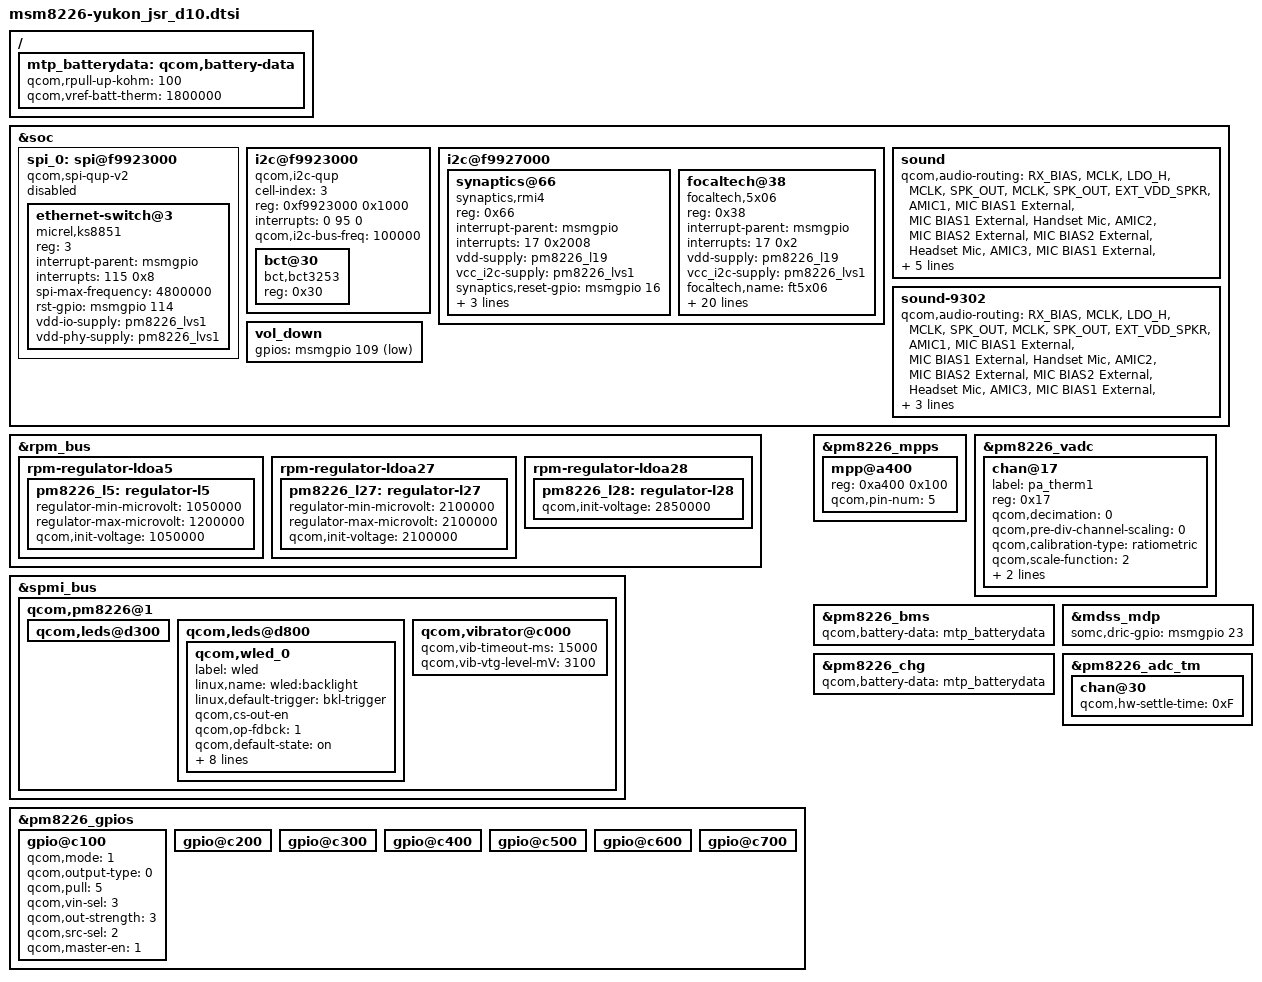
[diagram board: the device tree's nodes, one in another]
/* Copyright (c) 2013-2016, The Linux Foundation. All rights reserved.
 *
 * This program is free software; you can redistribute it and/or modify
 * it under the terms of the GNU General Public License version 2 and
 * only version 2 as published by the Free Software Foundation.
 *
 * This program is distributed in the hope that it will be useful,
 * but WITHOUT ANY WARRANTY; without even the implied warranty of
 * MERCHANTABILITY or FITNESS FOR A PARTICULAR PURPOSE.  See the
 * GNU General Public License for more details.
 */

#include "msm8226-yukon_common.dtsi"
#include "dsi-panel-nt35590-720p-auo-video.dtsi"
#include "dsi-panel-nt35590-720p-cmi-video.dtsi"
#include "dsi-panel-nt35521-720p-auo-asi-video.dtsi"
#include "dsi-panel-nt35521-720p-lg-video.dtsi"

&soc {
	spi@f9923000 {
		ethernet-switch@3 {
			compatible = "micrel,ks8851";
			reg = <3>;
			interrupt-parent = <&msmgpio>;
			interrupts = <115 0x8>;
			spi-max-frequency = <4800000>;
			rst-gpio = <&msmgpio 114 0>;
			vdd-io-supply = <&pm8226_lvs1>;
			vdd-phy-supply = <&pm8226_lvs1>;
		};
	};

	i2c@f9923000 {    /* BLSP-1 QUP-1 */
		cell-index = <3>;
		compatible = "qcom,i2c-qup";
		reg = <0xf9923000 0x1000>;
		#address-cells = <0x1>;
		#size-cells = <0x0>;
		reg-names = "qup_phys_addr";
		interrupts = <0 95 0>;
		interrupt-names = "qup_err_intr";
		qcom,i2c-bus-freq = <100000>;
		/* ---- msm-tricolor-leds ----  */
		bct@30 {
			compatible = "bct,bct3253";
			reg = <0x30>;
		};
	};

	i2c@f9927000 { /* BLSP1 QUP5 */
		synaptics@66 {
			compatible = "synaptics,rmi4";
			reg = <0x66>;
			interrupt-parent = <&msmgpio>;
			interrupts = <17 0x2008>;
			vdd-supply = <&pm8226_l19>;
			vcc_i2c-supply = <&pm8226_lvs1>;
			synaptics,reset-gpio = <&msmgpio 16 0x00>;
			synaptics,irq-gpio = <&msmgpio 17 0x2008>;
			synaptics,button-map = <139 102 158>;
			synaptics,i2c-pull-up;
			/* synaptics,power-down;    */ /* fully power down regulators in suspend  */
			/* synaptics,disable-gpios; */ /* specify to disable gpios in suspend (power saving) */
		};

		focaltech@38 {
			compatible = "focaltech,5x06";
			reg = <0x38>;
			interrupt-parent = <&msmgpio>;
			interrupts = <17 0x2>;
			vdd-supply = <&pm8226_l19>;
			vcc_i2c-supply = <&pm8226_lvs1>;
			focaltech,name = "ft5x06";
			focaltech,family-id = <0x0A>;
			focaltech,ignore-id-check;
			focaltech,reset-gpio = <&msmgpio 16 0x00>;
			focaltech,irq-gpio = <&msmgpio 17 0x00>;
			focaltech,display-coords = <0 0 720 1280>;
			focaltech,panel-coords = <0 0 720 1280>;
			focaltech,button-map = <139 102 158>;
			focaltech,no-force-update;
			focaltech,i2c-pull-up;
			focaltech,group-id = <1>;
			focaltech,hard-reset-delay-ms = <20>;
			focaltech,soft-reset-delay-ms = <150>;
			focaltech,num-max-touches = <5>;
			focaltech,fw-delay-aa-ms = <50>;
			focaltech,fw-delay-55-ms = <30>;
			focaltech,fw-upgrade-id1 = <0x79>;
			focaltech,fw-upgrade-id2 = <0x07>;
			focaltech,fw-delay-readid-ms = <10>;
			focaltech,fw-delay-era-flsh-ms = <2000>;
			focaltech,fw-auto-cal;
		};
	};

	sound {
		qcom,audio-routing =
			"RX_BIAS", "MCLK",
			"LDO_H", "MCLK",
			"SPK_OUT", "MCLK",
			"SPK_OUT", "EXT_VDD_SPKR",
			"AMIC1", "MIC BIAS1 External",
			"MIC BIAS1 External", "Handset Mic",
			"AMIC2", "MIC BIAS2 External",
			"MIC BIAS2 External", "Headset Mic",
			"AMIC3", "MIC BIAS1 External",
			"MIC BIAS1 External", "Analog Mic3",
			"AMIC4", "MIC BIAS3 External",
			"MIC BIAS3 External", "Analog Mic4";

		qcom,cdc-mclk-gpios = <&pm8226_gpios 1 0>;
		qcom,cdc-vdd-spkr-gpios = <&pm8226_gpios 2 0>;
	};

	sound-9302 {
		qcom,audio-routing =
			"RX_BIAS", "MCLK",
			"LDO_H", "MCLK",
			"SPK_OUT", "MCLK",
			"SPK_OUT", "EXT_VDD_SPKR",
			"AMIC1", "MIC BIAS1 External",
			"MIC BIAS1 External", "Handset Mic",
			"AMIC2", "MIC BIAS2 External",
			"MIC BIAS2 External", "Headset Mic",
			"AMIC3", "MIC BIAS1 External",
			"MIC BIAS1 External", "Handset Mic";

		qcom,cdc-mclk-gpios = <&pm8226_gpios 1 0>;
		qcom,cdc-vdd-spkr-gpios = <&pm8226_gpios 2 0>;
	};

	spi_0: spi@f9923000 { /* BLSP1 QUP1 */
		compatible = "qcom,spi-qup-v2";
		status = "disabled";
	};

	vol_down {
		gpios = <&msmgpio 109 0x1>;
	};
};

&rpm_bus {
	rpm-regulator-ldoa5 {
		pm8226_l5: regulator-l5 {
			regulator-min-microvolt = <1050000>;
			regulator-max-microvolt = <1200000>;
			qcom,init-voltage = <1050000>;
		};
	};

	rpm-regulator-ldoa27 {
		pm8226_l27: regulator-l27 {
			regulator-min-microvolt = <2100000>;
			regulator-max-microvolt = <2100000>;
			qcom,init-voltage = <2100000>;
		};
	};

	rpm-regulator-ldoa28 {
		pm8226_l28: regulator-l28 {
			qcom,init-voltage = <2850000>;
		};
	};
};

&spmi_bus {
	qcom,pm8226@1 {
		qcom,leds@d300 {
			status = "okay";
		};
		qcom,leds@d800 {
			status = "okay";
			qcom,wled_0 {
				label = "wled";
				linux,name = "wled:backlight";
				linux,default-trigger = "bkl-trigger";
				qcom,cs-out-en;
				qcom,op-fdbck = <1>;
				qcom,default-state = "on";
				qcom,max-current = <20>;
				qcom,ctrl-delay-us = <0>;
				qcom,boost-curr-lim = <3>;
				qcom,cp-sel = <0>;
				qcom,switch-freq = <11>;
				qcom,ovp-val = <0>;
				qcom,num-strings = <1>;
				qcom,id = <0>;
			};
		};
		qcom,vibrator@c000 {
			qcom,vib-timeout-ms = <15000>;
			qcom,vib-vtg-level-mV = <3100>;
		};
	};
};

&pm8226_gpios {
	gpio@c100 { /* GPIO 2 */
		qcom,mode = <1>;
		qcom,output-type = <0>;
		qcom,pull = <5>;
		qcom,vin-sel = <3>;
		qcom,out-strength = <3>;
		qcom,src-sel = <2>;
		qcom,master-en = <1>;
	};

	gpio@c200 { /* GPIO 3 */
	};

	gpio@c300 { /* GPIO 4 */
	};

	gpio@c400 { /* GPIO 5 */
	};

	gpio@c500 { /* GPIO 6 */
	};

	gpio@c600 { /* GPIO 7 */
	};

	gpio@c700 { /* GPIO 8 */
	};
};

&pm8226_mpps {
	/delete-node/ mpp@a400;
};

&pm8226_mpps {
	mpp@a400 { /* MPP 5 */
		reg = <0xa400 0x100>;
		qcom,pin-num = <5>;
	};
};

&pm8226_vadc {
	chan@17 {
		label = "pa_therm1";
		reg = <0x17>;
		qcom,decimation = <0>;
		qcom,pre-div-channel-scaling = <0>;
		qcom,calibration-type = "ratiometric";
		qcom,scale-function = <2>;
		qcom,hw-settle-time = <2>;
		qcom,fast-avg-setup = <0>;
	};
};

/ {
	mtp_batterydata: qcom,battery-data {
		qcom,rpull-up-kohm = <100>;
		qcom,vref-batt-therm = <1800000>;

		#include "batterydata-jsr-4v35-3000mah.dtsi"
		#include "batterydata-jsr-4v35-6000mah.dtsi"
		#include "batterydata-jsr-4v35-3000mah-ruilong.dtsi"
		#include "batterydata-jsr-4v35-6000mah-ruilong.dtsi"
	};
};

&pm8226_bms {
	qcom,battery-data = <&mtp_batterydata>;
};

&pm8226_chg {
	qcom,battery-data = <&mtp_batterydata>;
};

&mdss_mdp {
	somc,dric-gpio = <&msmgpio 23 0>;
};

&pm8226_adc_tm {
	/* Channel Node */
	chan@30 {
		qcom,hw-settle-time = <0xF>;
	};
};
